# ETHACS register map
Registers from a debugger description file.
Registers are 32-bit, access not given, no defined reset value unless marked. A register's access mark holds for its fields unless they carry their own. Addresses are absolute; registers are grouped by the start of their names; lines under a group give offsets from that group; [hi:lo] are bit positions; {n}, {i} and the like mark numbered series; 'fields as' and 'values as' point back to an identical list; <NAME> marks a mode.

## SFR
0x44030000 PRCMD
  [0] PRCMD
0x44030004 ESIDCODE ro
  [31:0] ES_IDCODE
0x44030008 MODCTRL
  [4:0] SW_MODE
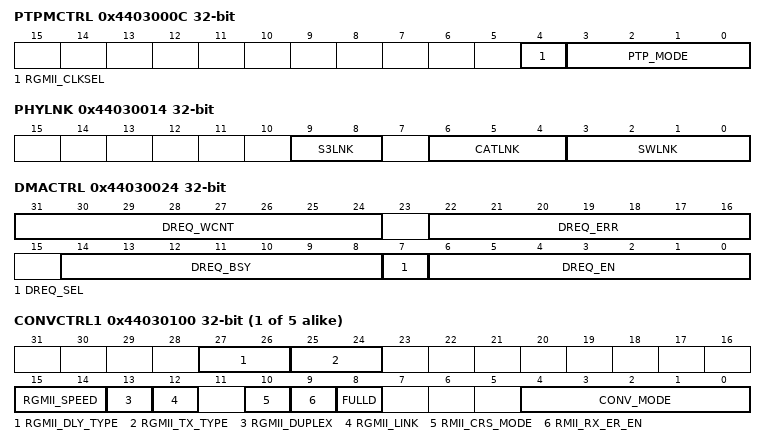
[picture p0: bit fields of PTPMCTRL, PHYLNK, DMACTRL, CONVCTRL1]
0x4403000C PTPMCTRL
  [4] RGMII_CLKSEL, [3:0] PTP_MODE
0x44030014 PHYLNK
  [9:8] S3LNK, [6:4] CATLNK, [3:0] SWLNK
0x44030020 PTCTRL
  [2:0] TRG_SEL
0x44030024 DMACTRL
  [31:24] DREQ_WCNT, [22:16] DREQ_ERR, [14:8] DREQ_BSY ro, [7] DREQ_SEL, [6:0] DREQ_EN
{0x440300FC+4i} CONVCTRL{i} (i=1..5)
  [27:26] RGMII_DLY_TYPE ro, [25:24] RGMII_TX_TYPE ro, [15:14] RGMII_SPEED ro, [13] RGMII_DUPLEX ro, [12] RGMII_LINK ro, [10] RMII_CRS_MODE, [9] RMII_RX_ER_EN, [8] FULLD, [4:0] CONV_MODE
0x44030114 CONVRST
  [4:0] PHYIF_RSTn
0x44030200 ECATOFFADR
  [4:0] OADD
0x44030204 ECATOPMOD
  [0] I2CSIZE
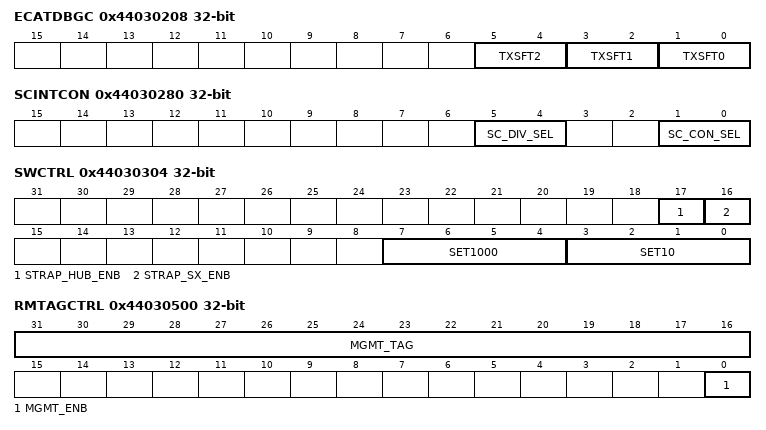
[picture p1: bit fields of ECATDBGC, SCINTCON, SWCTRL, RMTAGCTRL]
0x44030208 ECATDBGC
  [5:4] TXSFT2, [3:2] TXSFT1, [1:0] TXSFT0
0x44030280 SCINTCON
  [5:4] SC_DIV_SEL, [1:0] SC_CON_SEL
0x44030304 SWCTRL
  [17] STRAP_HUB_ENB, [16] STRAP_SX_ENB, [7:4] SET1000, [3:0] SET10
0x44030308 SWDUPC
  [3:0] PHY_DUPLEX
0x44030500 RMTAGCTRL
  [31:16] MGMT_TAG, [0] MGMT_ENB
0x44030600 HSRMOD ro
  [0] HSR_SEL
